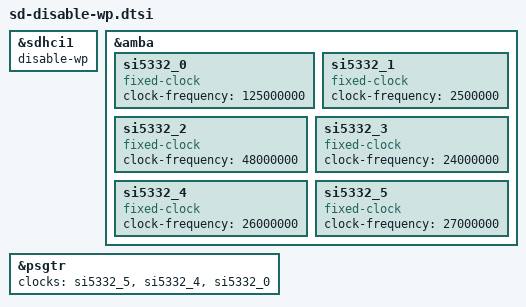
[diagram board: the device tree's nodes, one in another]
&sdhci1 {
    disable-wp;
};

&amba {
    si5332_0: si5332_0 {
		#clock-cells = <0>;
		clock-frequency = <125000000>;
		compatible = "fixed-clock";
	};
    si5332_1: si5332_1 {
		#clock-cells = <0>;
		clock-frequency = <2500000>;
		compatible = "fixed-clock";
	};
    si5332_2: si5332_2 {
		#clock-cells = <0>;
		clock-frequency = <48000000>;
		compatible = "fixed-clock";
	};
    si5332_3: si5332_3 {
		#clock-cells = <0>;
		clock-frequency = <24000000>;
		compatible = "fixed-clock";
	};
    si5332_4: si5332_4 {
		#clock-cells = <0>;
		clock-frequency = <26000000>;
		compatible = "fixed-clock";
	};
    si5332_5: si5332_5 {
		#clock-cells = <0>;
		clock-frequency = <27000000>;
		compatible = "fixed-clock";
	};
};

&psgtr {
    clocks = <&si5332_5>, <&si5332_4>, <&si5332_0>;
    clock-names = "ref0", "ref1", "ref2";
};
